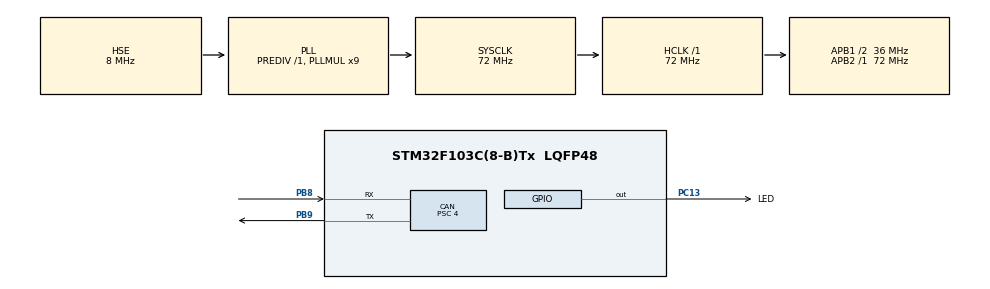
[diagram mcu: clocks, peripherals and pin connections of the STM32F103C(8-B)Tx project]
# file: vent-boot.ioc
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CAN.BS1=CAN_BS1_15TQ
CAN.BS2=CAN_BS2_2TQ
CAN.CalculateBaudRate=500000
CAN.CalculateTimeBit=2000
CAN.CalculateTimeQuantum=111.11111111111111
CAN.Prescaler=4
IWDG.Prescaler=IWDG_PRESCALER_32
Mcu.Family=STM32F1
Mcu.Name=STM32F103C(8-B)Tx
Mcu.Package=LQFP48
NVIC.PriorityGroup=NVIC_PRIORITYGROUP_4
NVIC.USB_LP_CAN1_RX0_IRQn=true\:0\:0\:false\:false\:true\:true\:true\:true
PA13.Mode=Serial_Wire
PA13.Signal=SYS_JTMS-SWDIO
PA14.Mode=Serial_Wire
PA14.Signal=SYS_JTCK-SWCLK
PB8.Mode=CAN_Activate
PB8.Signal=CAN_RX
PB9.Mode=CAN_Activate
PB9.Signal=CAN_TX
PC13-TAMPER-RTC.GPIO_Label=LED
PC13-TAMPER-RTC.Signal=GPIO_Output
PD0-OSC_IN.Mode=HSE-External-Oscillator
PD0-OSC_IN.Signal=RCC_OSC_IN
PD1-OSC_OUT.Mode=HSE-External-Oscillator
PD1-OSC_OUT.Signal=RCC_OSC_OUT
ProjectManager.HeapSize=0x200
ProjectManager.StackSize=0x400
ProjectManager.TargetToolchain=STM32CubeIDE
RCC.AHBFreq_Value=72000000
RCC.APB1CLKDivider=RCC_HCLK_DIV2
RCC.APB1Freq_Value=36000000
RCC.APB1TimFreq_Value=72000000
RCC.APB2Freq_Value=72000000
RCC.APB2TimFreq_Value=72000000
RCC.HCLKFreq_Value=72000000
RCC.PLLMUL=RCC_PLL_MUL9
RCC.PLLSourceVirtual=RCC_PLLSOURCE_HSE
RCC.SYSCLKFreq_VALUE=72000000
RCC.SYSCLKSource=RCC_SYSCLKSOURCE_PLLCLK
RCC.USBFreq_Value=72000000
VP_CRC_VS_CRC.Mode=CRC_Activate
VP_IWDG_VS_IWDG.Mode=IWDG_Activate
board=custom

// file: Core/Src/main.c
/* USER CODE BEGIN Header */
/**
  ******************************************************************************
  * @file           : main.c
  * @brief          : Main program body
  ******************************************************************************
  * @attention
  *
  * Copyright (c) 2026 STMicroelectronics.
  * All rights reserved.
  *
  * This software is licensed under terms that can be found in the LICENSE file
  * in the root directory of this software component.
  * If no LICENSE file comes with this software, it is provided AS-IS.
  *
  ******************************************************************************
  */
/* USER CODE END Header */
#include "main.h"

/* USER CODE BEGIN Includes */
#include <common_param.h>
#include <weak_common_param.h>
/* USER CODE END Includes */

CAN_HandleTypeDef hcan;

CRC_HandleTypeDef hcrc;

IWDG_HandleTypeDef hiwdg;

/* USER CODE BEGIN PV */
uint32_t inhibit_autorun = 0;
uint16_t config_number = 0;
uint32_t xcp_base_id = XCP_BASE_ID;
common_param_t param = {};

volatile const __attribute__((section(".calib_flash_sec"))) common_param_t param_flash;

const common_param_t param_def =
{
	.crc = 0,
	.size = COMMON_PARAM_SIZE,
	.xcp_canid_rx = XCP_BASE_ID,
	.xcp_canid_tx = XCP_BASE_ID + 1,
	.uds_canid_rx = 0,
	.uds_canid_func = 0,
	.uds_canid_tx = 0,
	.ip_mac = {},
	.ip_v4 = {},
	.ip_port_xcp = 0,
	.id = 0
};
/* USER CODE END PV */

void SystemClock_Config(void);
static void MX_GPIO_Init(void);
static void MX_CAN_Init(void);
static void MX_CRC_Init(void);
static void MX_IWDG_Init(void);
/* USER CODE BEGIN PFP */
void deinit_perif(void);
void try_read_xcp_id(void);
void load_param(void);
/* USER CODE END PFP */

/* USER CODE BEGIN 0 */

void deinit_perif(void)
{
	__disable_irq ();
	SysTick->CTRL = 0;
	HAL_CAN_DeInit(&hcan);
	HAL_CAN_DeactivateNotification(&hcan, 0xFFFFFFFF);
//	HAL_NVIC_DisableIRQ(TIM15_IRQn);
	HAL_NVIC_DisableIRQ(CAN1_RX0_IRQn);
//	HAL_NVIC_ClearPendingIRQ(TIM15_IRQn);
	HAL_NVIC_ClearPendingIRQ(CAN1_RX0_IRQn);
	HAL_NVIC_ClearPendingIRQ(SysTick_IRQn);
	HAL_RCC_DeInit();
}

void HAL_CAN_RxFifo0MsgPendingCallback(CAN_HandleTypeDef *hcan)
{
	CAN_RxHeaderTypeDef rx_header;
	uint8_t data[8];

	if(HAL_CAN_GetRxMessage(hcan, CAN_RX_FIFO0, &rx_header, data) != HAL_OK) return;

	can_platform_msg_recieve(&rx_header, data);

}

void HAL_CAN_RxFifo0FullCallback(CAN_HandleTypeDef *hcan)
{
	HAL_CAN_RxFifo0MsgPendingCallback(hcan);
}

void HAL_CAN_ErrorCallback(CAN_HandleTypeDef *hcan)
{
	return;
}
/* USER CODE END 0 */

int main(void)
{

  /* MCU Configuration--------------------------------------------------------*/

  /* Reset of all peripherals, Initializes the Flash interface and the Systick. */
  HAL_Init();

  /* Configure the system clock */
  SystemClock_Config();

  /* Initialize all configured peripherals */
  MX_GPIO_Init();
  MX_CAN_Init();
  MX_CRC_Init();
  MX_IWDG_Init();
  /* USER CODE BEGIN 2 */

  can_platform_init();

  load_param();
  try_read_xcp_id();

  xcp_can_init(0, 0, xcp_base_id);

  PWR->CR |= PWR_CR_DBP;
  if(BKP->DR1 == BOOT_MSG_XCP_REQ)
  {
  	inhibit_autorun = 1;
  	CAN_RxHeaderTypeDef CAN_RxHeader;
  	CAN_RxHeader.StdId = xcp_base_id;
  	uint8_t data[8] = {0xD2, 0, 0, 0, 0, 0, 0, 0};
  	can_platform_msg_recieve(&CAN_RxHeader, data);
  }

  BKP->DR1 = BOOT_MGG_CLEAR;

  __enable_irq();
  /* USER CODE END 2 */

  /* Infinite loop */
  while (1)
  {

    /* USER CODE BEGIN 3 */
	  xcp_can_poll();
	  if(HAL_GetTick() > 5000 && !inhibit_autorun)
	  {

		  go_to_application();
	  }
	  uint32_t tick = HAL_GetTick() % 1000;
	  if(tick < 100)
	  {
		  HAL_GPIO_WritePin(LED_GPIO_Port, LED_Pin, GPIO_PIN_RESET);
	  }
	  else if(inhibit_autorun && tick >= 200 && tick < 300)
	  {
		  HAL_GPIO_WritePin(LED_GPIO_Port, LED_Pin, GPIO_PIN_RESET);
	  }
	  else
	  {
		  HAL_GPIO_WritePin(LED_GPIO_Port, LED_Pin, GPIO_PIN_SET);
	  }

	  HAL_IWDG_Refresh(&hiwdg);
  }
  /* USER CODE END 3 */
}

void SystemClock_Config(void)
{
  RCC_OscInitTypeDef RCC_OscInitStruct = {0};
  RCC_ClkInitTypeDef RCC_ClkInitStruct = {0};

  /** Initializes the RCC Oscillators according to the specified parameters
  * in the RCC_OscInitTypeDef structure.
  */
  RCC_OscInitStruct.OscillatorType = RCC_OSCILLATORTYPE_LSI|RCC_OSCILLATORTYPE_HSE;
  RCC_OscInitStruct.HSEState = RCC_HSE_ON;
  RCC_OscInitStruct.HSEPredivValue = RCC_HSE_PREDIV_DIV1;
  RCC_OscInitStruct.HSIState = RCC_HSI_ON;
  RCC_OscInitStruct.LSIState = RCC_LSI_ON;
  RCC_OscInitStruct.PLL.PLLState = RCC_PLL_ON;
  RCC_OscInitStruct.PLL.PLLSource = RCC_PLLSOURCE_HSE;
  RCC_OscInitStruct.PLL.PLLMUL = RCC_PLL_MUL9;
  if (HAL_RCC_OscConfig(&RCC_OscInitStruct) != HAL_OK)
  {
    Error_Handler();
  }

  /** Initializes the CPU, AHB and APB buses clocks
  */
  RCC_ClkInitStruct.ClockType = RCC_CLOCKTYPE_HCLK|RCC_CLOCKTYPE_SYSCLK
                              |RCC_CLOCKTYPE_PCLK1|RCC_CLOCKTYPE_PCLK2;
  RCC_ClkInitStruct.SYSCLKSource = RCC_SYSCLKSOURCE_PLLCLK;
  RCC_ClkInitStruct.AHBCLKDivider = RCC_SYSCLK_DIV1;
  RCC_ClkInitStruct.APB1CLKDivider = RCC_HCLK_DIV2;
  RCC_ClkInitStruct.APB2CLKDivider = RCC_HCLK_DIV1;

  if (HAL_RCC_ClockConfig(&RCC_ClkInitStruct, FLASH_LATENCY_2) != HAL_OK)
  {
    Error_Handler();
  }
}

static void MX_CAN_Init(void)
{

  hcan.Instance = CAN1;
  hcan.Init.Prescaler = 4;
  hcan.Init.Mode = CAN_MODE_NORMAL;
  hcan.Init.SyncJumpWidth = CAN_SJW_1TQ;
  hcan.Init.TimeSeg1 = CAN_BS1_15TQ;
  hcan.Init.TimeSeg2 = CAN_BS2_2TQ;
  hcan.Init.TimeTriggeredMode = DISABLE;
  hcan.Init.AutoBusOff = DISABLE;
  hcan.Init.AutoWakeUp = DISABLE;
  hcan.Init.AutoRetransmission = DISABLE;
  hcan.Init.ReceiveFifoLocked = DISABLE;
  hcan.Init.TransmitFifoPriority = DISABLE;
  if (HAL_CAN_Init(&hcan) != HAL_OK)
  {
    Error_Handler();
  }

}

static void MX_CRC_Init(void)
{

  hcrc.Instance = CRC;
  if (HAL_CRC_Init(&hcrc) != HAL_OK)
  {
    Error_Handler();
  }

}

static void MX_IWDG_Init(void)
{

  hiwdg.Instance = IWDG;
  hiwdg.Init.Prescaler = IWDG_PRESCALER_32;
  hiwdg.Init.Reload = 4095;
  if (HAL_IWDG_Init(&hiwdg) != HAL_OK)
  {
    Error_Handler();
  }

}

static void MX_GPIO_Init(void)
{
  GPIO_InitTypeDef GPIO_InitStruct = {0};

  /* GPIO Ports Clock Enable */
  __HAL_RCC_GPIOC_CLK_ENABLE();
  __HAL_RCC_GPIOD_CLK_ENABLE();
  __HAL_RCC_GPIOA_CLK_ENABLE();
  __HAL_RCC_GPIOB_CLK_ENABLE();

  /*Configure GPIO pin Output Level */
  HAL_GPIO_WritePin(LED_GPIO_Port, LED_Pin, GPIO_PIN_RESET);

  /*Configure GPIO pin : LED_Pin */
  GPIO_InitStruct.Pin = LED_Pin;
  GPIO_InitStruct.Mode = GPIO_MODE_OUTPUT_PP;
  GPIO_InitStruct.Pull = GPIO_NOPULL;
  GPIO_InitStruct.Speed = GPIO_SPEED_FREQ_LOW;
  HAL_GPIO_Init(LED_GPIO_Port, &GPIO_InitStruct);

}

/* USER CODE BEGIN 4 */
void try_read_xcp_id(void)
{
	if(param.xcp_canid_tx == param.xcp_canid_rx + 1 && param.xcp_canid_rx != 0xFFFFFFFF)
	{
		xcp_base_id = param.xcp_canid_rx;
	}
	else
	{
		xcp_base_id += config_number * 2;
	}
}

void load_param(void)
{
	uint32_t crc = 0;

	// Load defaul params
	memcpy(&param, &param_def, param_def.size);

	//Check saved params and load
	if(param_flash.size <= (SECTORS_FOR_PARAM * SECTOR_SIZE) && (param_flash.size != 0) && (param_flash.size % 4 == 0))
	{
		crc = HAL_CRC_Calculate(&hcrc, (uint32_t*)&param_flash.size, param_flash.size / 4 - 1);
		if(param_flash.crc == crc)
		{
			memcpy(&param, (const void *)&param_flash, param_flash.size);
		}
	}

	//Recalc CRC
	crc = HAL_CRC_Calculate(&hcrc, (uint32_t*)&param.size, param.size / 4 - 1);
	param.crc = crc;
}
/* USER CODE END 4 */

void Error_Handler(void)
{
  __disable_irq();
  while (1)
  {
  }
}
